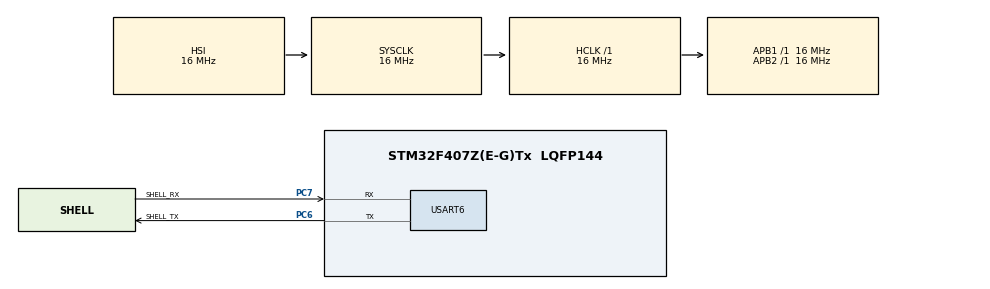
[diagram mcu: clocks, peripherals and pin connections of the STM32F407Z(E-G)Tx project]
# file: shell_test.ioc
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Dma.Request0=USART6_RX
Dma.USART6_RX.0.Direction=DMA_PERIPH_TO_MEMORY
Dma.USART6_RX.0.FIFOMode=DMA_FIFOMODE_DISABLE
Dma.USART6_RX.0.Instance=DMA2_Stream1
Dma.USART6_RX.0.MemDataAlignment=DMA_MDATAALIGN_BYTE
Dma.USART6_RX.0.MemInc=DMA_MINC_ENABLE
Dma.USART6_RX.0.Mode=DMA_NORMAL
Dma.USART6_RX.0.PeriphDataAlignment=DMA_PDATAALIGN_BYTE
Dma.USART6_RX.0.PeriphInc=DMA_PINC_DISABLE
Dma.USART6_RX.0.Priority=DMA_PRIORITY_LOW
FREERTOS.Tasks01=defaultTask,0,128,StartDefaultTask,Default,NULL
Mcu.Family=STM32F4
Mcu.Name=STM32F407Z(E-G)Tx
Mcu.Package=LQFP144
NVIC.DMA2_Stream1_IRQn=true\:5\:0\:false\:false\:true\:true\:false\:true
NVIC.PriorityGroup=NVIC_PRIORITYGROUP_4
NVIC.USART6_IRQn=true\:5\:0\:false\:false\:true\:true\:true\:true
PA13.Mode=Serial_Wire
PA13.Signal=SYS_JTMS-SWDIO
PA14.Mode=Serial_Wire
PA14.Signal=SYS_JTCK-SWCLK
PC6.GPIO_Label=SHELL_TX
PC6.Mode=Asynchronous
PC6.Signal=USART6_TX
PC7.GPIO_Label=SHELL_RX
PC7.Mode=Asynchronous
PC7.Signal=USART6_RX
ProjectManager.HeapSize=0x200
ProjectManager.StackSize=0x400
ProjectManager.TargetToolchain=TrueSTUDIO
RCC.AHBFreq_Value=16000000
RCC.APB1Freq_Value=16000000
RCC.APB2Freq_Value=16000000
RCC.CortexFreq_Value=16000000
RCC.HSE_VALUE=25000000
RCC.HSI_VALUE=16000000
RCC.LSE_VALUE=32768
RCC.SYSCLKFreq_VALUE=16000000
RCC.VCOOutputFreq_Value=192000000
USART6.VirtualMode=VM_ASYNC
VP_FREERTOS_VS_CMSIS_V1.Mode=CMSIS_V1
board=custom

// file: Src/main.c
/* USER CODE BEGIN Header */
/**
  ******************************************************************************
  * @file           : main.c
  * @brief          : Main program body
  ******************************************************************************
  * @attention
  *
  * <h2><center>&copy; Copyright (c) 2019 STMicroelectronics.
  * All rights reserved.</center></h2>
  *
  * This software component is licensed by ST under Ultimate Liberty license
  * SLA0044, the "License"; You may not use this file except in compliance with
  * the License. You may obtain a copy of the License at:
  *                             www.st.com/SLA0044
  *
  ******************************************************************************
  */
/* USER CODE END Header */

#include "main.h"
#include "cmsis_os.h"
#include "dma.h"
#include "usart.h"
#include "gpio.h"

void SystemClock_Config(void);
void MX_FREERTOS_Init(void);

int main(void)
{

  /* MCU Configuration--------------------------------------------------------*/

  /* Reset of all peripherals, Initializes the Flash interface and the Systick. */
  HAL_Init();

  /* Configure the system clock */
  SystemClock_Config();

  /* Initialize all configured peripherals */
  MX_GPIO_Init();
  MX_DMA_Init();
  MX_USART6_UART_Init();

  /* Call init function for freertos objects (in freertos.c) */
  MX_FREERTOS_Init();

  /* Start scheduler */
  osKernelStart();

  /* We should never get here as control is now taken by the scheduler */

  /* Infinite loop */
  while (1)
  {

  }
}

void SystemClock_Config(void)
{
  RCC_OscInitTypeDef RCC_OscInitStruct = {0};
  RCC_ClkInitTypeDef RCC_ClkInitStruct = {0};

  /** Configure the main internal regulator output voltage
  */
  __HAL_RCC_PWR_CLK_ENABLE();
  __HAL_PWR_VOLTAGESCALING_CONFIG(PWR_REGULATOR_VOLTAGE_SCALE1);
  /** Initializes the CPU, AHB and APB busses clocks
  */
  RCC_OscInitStruct.OscillatorType = RCC_OSCILLATORTYPE_HSI;
  RCC_OscInitStruct.HSIState = RCC_HSI_ON;
  RCC_OscInitStruct.HSICalibrationValue = RCC_HSICALIBRATION_DEFAULT;
  RCC_OscInitStruct.PLL.PLLState = RCC_PLL_NONE;
  if (HAL_RCC_OscConfig(&RCC_OscInitStruct) != HAL_OK)
  {
    Error_Handler();
  }
  /** Initializes the CPU, AHB and APB busses clocks
  */
  RCC_ClkInitStruct.ClockType = RCC_CLOCKTYPE_HCLK|RCC_CLOCKTYPE_SYSCLK
                              |RCC_CLOCKTYPE_PCLK1|RCC_CLOCKTYPE_PCLK2;
  RCC_ClkInitStruct.SYSCLKSource = RCC_SYSCLKSOURCE_HSI;
  RCC_ClkInitStruct.AHBCLKDivider = RCC_SYSCLK_DIV1;
  RCC_ClkInitStruct.APB1CLKDivider = RCC_HCLK_DIV1;
  RCC_ClkInitStruct.APB2CLKDivider = RCC_HCLK_DIV1;

  if (HAL_RCC_ClockConfig(&RCC_ClkInitStruct, FLASH_LATENCY_0) != HAL_OK)
  {
    Error_Handler();
  }
}

void Error_Handler(void)
{
}

/************************ (C) COPYRIGHT STMicroelectronics *****END OF FILE****/

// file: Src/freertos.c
/* USER CODE BEGIN Header */
/**
  ******************************************************************************
  * File Name          : freertos.c
  * Description        : Code for freertos applications
  ******************************************************************************
  * @attention
  *
  * <h2><center>&copy; Copyright (c) 2019 STMicroelectronics.
  * All rights reserved.</center></h2>
  *
  * This software component is licensed by ST under Ultimate Liberty license
  * SLA0044, the "License"; You may not use this file except in compliance with
  * the License. You may obtain a copy of the License at:
  *                             www.st.com/SLA0044
  *
  ******************************************************************************
  */
/* USER CODE END Header */

#include "FreeRTOS.h"
#include "task.h"
#include "main.h"
#include "cmsis_os.h"

/* USER CODE BEGIN Includes */
#include "uartbsp.h"
#include "shell.h"
/* USER CODE END Includes */

osThreadId defaultTaskHandle;

void StartDefaultTask(void const * argument);

void MX_FREERTOS_Init(void); /* (MISRA C 2004 rule 8.1) */

void MX_FREERTOS_Init(void) {

  /* Create the thread(s) */
  /* definition and creation of defaultTask */
  osThreadDef(defaultTask, StartDefaultTask, osPriorityNormal, 0, 128);
  defaultTaskHandle = osThreadCreate(osThread(defaultTask), NULL);

}

void StartDefaultTask(void const * argument)
{

  /* USER CODE BEGIN StartDefaultTask */

	vUartBspInit ();
	Shell_Init ();
  /* Infinite loop */
  for(;;)
  {
//	  printf ("hello world\n");
	  Shell_Mode ();
    osDelay(20);
  }
  /* USER CODE END StartDefaultTask */
}

/************************ (C) COPYRIGHT STMicroelectronics *****END OF FILE****/
